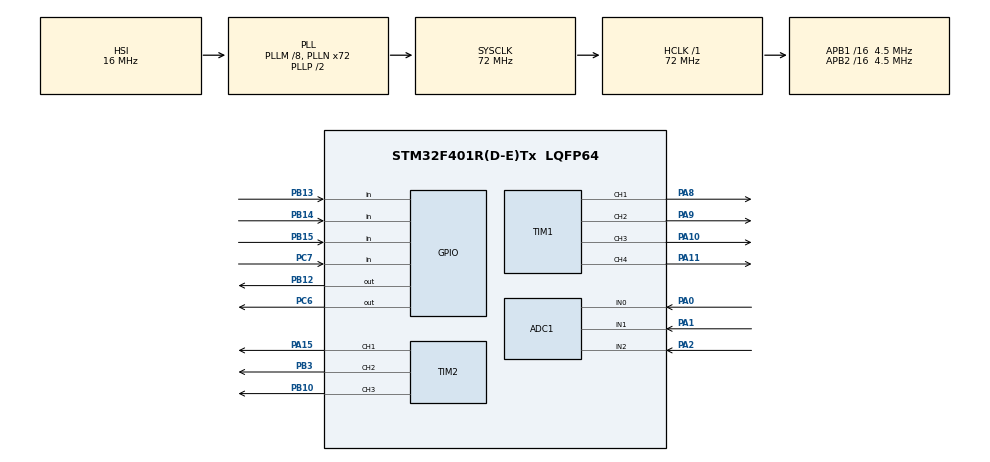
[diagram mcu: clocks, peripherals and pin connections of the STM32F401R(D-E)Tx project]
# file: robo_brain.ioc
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ADC1.Channel-0\#ChannelRegularConversion=ADC_CHANNEL_0
ADC1.NbrOfConversionFlag=1
ADC1.Rank-0\#ChannelRegularConversion=1
ADC1.SamplingTime-0\#ChannelRegularConversion=ADC_SAMPLETIME_3CYCLES
ADC1.master=1
Mcu.Family=STM32F4
Mcu.Name=STM32F401R(D-E)Tx
Mcu.Package=LQFP64
NVIC.PriorityGroup=NVIC_PRIORITYGROUP_4
PA0-WKUP.Signal=ADCx_IN0
PA1.Signal=ADCx_IN1
PA10.Signal=S_TIM1_CH3
PA11.Signal=S_TIM1_CH4
PA15.Signal=S_TIM2_CH1_ETR
PA2.Signal=ADCx_IN2
PA8.Signal=S_TIM1_CH1
PA9.Signal=S_TIM1_CH2
PB10.Signal=S_TIM2_CH3
PB12.Signal=GPIO_Output
PB13.Signal=GPIO_Input
PB14.Signal=GPIO_Input
PB15.Signal=GPIO_Input
PB3.Signal=S_TIM2_CH2
PC6.Signal=GPIO_Output
PC7.Signal=GPIO_Input
ProjectManager.HeapSize=0x200
ProjectManager.StackSize=0x400
ProjectManager.TargetToolchain=Makefile
RCC.48MHZClocksFreq_Value=36000000
RCC.AHBFreq_Value=72000000
RCC.APB1CLKDivider=RCC_HCLK_DIV16
RCC.APB1Freq_Value=4500000
RCC.APB1TimFreq_Value=9000000
RCC.APB2CLKDivider=RCC_HCLK_DIV16
RCC.APB2Freq_Value=4500000
RCC.APB2TimFreq_Value=9000000
RCC.CortexFreq_Value=72000000
RCC.HCLKFreq_Value=72000000
RCC.HSE_VALUE=25000000
RCC.HSI_VALUE=16000000
RCC.LSE_VALUE=32768
RCC.PLLM=8
RCC.PLLN=72
RCC.SYSCLKFreq_VALUE=72000000
RCC.SYSCLKSource=RCC_SYSCLKSOURCE_PLLCLK
RCC.VCOOutputFreq_Value=144000000
SH.ADCx_IN0.0=ADC1_IN0,IN0
SH.ADCx_IN1.0=ADC1_IN1,IN1
SH.ADCx_IN2.0=ADC1_IN2,IN2
SH.S_TIM1_CH1.0=TIM1_CH1,PWM Generation1 CH1
SH.S_TIM1_CH2.0=TIM1_CH2,PWM Generation2 CH2
SH.S_TIM1_CH3.0=TIM1_CH3,PWM Generation3 CH3
SH.S_TIM1_CH4.0=TIM1_CH4,PWM Generation4 CH4
SH.S_TIM2_CH1_ETR.0=TIM2_CH1,PWM Generation1 CH1
SH.S_TIM2_CH2.0=TIM2_CH2,PWM Generation2 CH2
SH.S_TIM2_CH3.0=TIM2_CH3,PWM Generation3 CH3
TIM1.Channel-PWM\ Generation1\ CH1=TIM_CHANNEL_1
TIM1.Channel-PWM\ Generation2\ CH2=TIM_CHANNEL_2
TIM1.Channel-PWM\ Generation3\ CH3=TIM_CHANNEL_3
TIM1.Channel-PWM\ Generation4\ CH4=TIM_CHANNEL_4
TIM2.Channel-PWM\ Generation1\ CH1=TIM_CHANNEL_1
TIM2.Channel-PWM\ Generation2\ CH2=TIM_CHANNEL_2
TIM2.Channel-PWM\ Generation3\ CH3=TIM_CHANNEL_3
VP_TIM1_VS_ClockSourceINT.Mode=Internal
VP_TIM2_VS_ClockSourceINT.Mode=Internal
board=custom

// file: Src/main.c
/**
 ******************************************************************************
 * @file           : main.c
 * @brief          : Main program body
 ******************************************************************************
 ** This notice applies to any and all portions of this file
 * that are not between comment pairs USER CODE BEGIN and
 * USER CODE END. Other portions of this file, whether
 * inserted by the user or by software development tools
 * are owned by their respective copyright owners.
 *
 * COPYRIGHT(c) 2018 STMicroelectronics
 *
 * Redistribution and use in source and binary forms, with or without modification,
 * are permitted provided that the following conditions are met:
 *   1. Redistributions of source code must retain the above copyright notice,
 *      this list of conditions and the following disclaimer.
 *   2. Redistributions in binary form must reproduce the above copyright notice,
 *      this list of conditions and the following disclaimer in the documentation
 *      and/or other materials provided with the distribution.
 *   3. Neither the name of STMicroelectronics nor the names of its contributors
 *      may be used to endorse or promote products derived from this software
 *      without specific prior written permission.
 *
 * THIS SOFTWARE IS PROVIDED BY THE COPYRIGHT HOLDERS AND CONTRIBUTORS "AS IS"
 * AND ANY EXPRESS OR IMPLIED WARRANTIES, INCLUDING, BUT NOT LIMITED TO, THE
 * IMPLIED WARRANTIES OF MERCHANTABILITY AND FITNESS FOR A PARTICULAR PURPOSE ARE
 * DISCLAIMED. IN NO EVENT SHALL THE COPYRIGHT HOLDER OR CONTRIBUTORS BE LIABLE
 * FOR ANY DIRECT, INDIRECT, INCIDENTAL, SPECIAL, EXEMPLARY, OR CONSEQUENTIAL
 * DAMAGES (INCLUDING, BUT NOT LIMITED TO, PROCUREMENT OF SUBSTITUTE GOODS OR
 * SERVICES; LOSS OF USE, DATA, OR PROFITS; OR BUSINESS INTERRUPTION) HOWEVER
 * CAUSED AND ON ANY THEORY OF LIABILITY, WHETHER IN CONTRACT, STRICT LIABILITY,
 * OR TORT (INCLUDING NEGLIGENCE OR OTHERWISE) ARISING IN ANY WAY OUT OF THE USE
 * OF THIS SOFTWARE, EVEN IF ADVISED OF THE POSSIBILITY OF SUCH DAMAGE.
 *
 ******************************************************************************
 */
#include "main.h"
#include "stm32f4xx_hal.h"

/* USER CODE BEGIN Includes */
#include "tm_stm32f4_hcsr04.h"
/* USER CODE END Includes */

ADC_HandleTypeDef hadc1;

TIM_HandleTypeDef htim1;
TIM_HandleTypeDef htim2;

/* USER CODE BEGIN PV */
/* Private variables ---------------------------------------------------------*/

/* USER CODE END PV */

void SystemClock_Config(void);
static void MX_GPIO_Init(void);
static void MX_ADC1_Init(void);
static void MX_TIM1_Init(void);
static void MX_TIM2_Init(void);

void HAL_TIM_MspPostInit(TIM_HandleTypeDef *htim);

/* USER CODE BEGIN PFP */
/* Private function prototypes -----------------------------------------------*/

/* USER CODE END PFP */

int main(void)
{
    /* USER CODE BEGIN 1 */
    TM_HCSR04_t SONAR_LEFT;
    TM_HCSR04_t SONAR_RIGHT;
    /* USER CODE END 1 */

    /* MCU Configuration----------------------------------------------------------*/

    /* Reset of all peripherals, Initializes the Flash interface and the Systick. */
    HAL_Init();

    /* USER CODE BEGIN Init */

    /* Initialize distance sensor1 on pins; ECHO: PC7, TRIGGER: PC6 */
    if (!TM_HCSR04_Init(&SONAR_LEFT, GPIOC, GPIO_PIN_7, GPIOC, GPIO_PIN_6)) {
        /* Sensor is not working */
    }
    /* Initialize distance sensor1 on pins; ECHO: PC12, TRIGGER: PC13 */
    if (!TM_HCSR04_Init(&SONAR_RIGHT, GPIOC, GPIO_PIN_12, GPIOC, GPIO_PIN_13)) {
        /* Sensor is not working */
    }
    /* USER CODE END Init */

    /* Configure the system clock */
    SystemClock_Config();

    /* Initialize all configured peripherals */
    MX_GPIO_Init();
    MX_ADC1_Init();
    MX_TIM1_Init();
    MX_TIM2_Init();

    /* Infinite loop */
    while (1)
    {

    }

}

void SystemClock_Config(void)
{

    RCC_OscInitTypeDef RCC_OscInitStruct;
    RCC_ClkInitTypeDef RCC_ClkInitStruct;

    /**Configure the main internal regulator output voltage
    */
    __HAL_RCC_PWR_CLK_ENABLE();

    __HAL_PWR_VOLTAGESCALING_CONFIG(PWR_REGULATOR_VOLTAGE_SCALE2);

    /**Initializes the CPU, AHB and APB busses clocks
    */
    RCC_OscInitStruct.OscillatorType = RCC_OSCILLATORTYPE_HSI;
    RCC_OscInitStruct.HSIState = RCC_HSI_ON;
    RCC_OscInitStruct.HSICalibrationValue = 16;
    RCC_OscInitStruct.PLL.PLLState = RCC_PLL_ON;
    RCC_OscInitStruct.PLL.PLLSource = RCC_PLLSOURCE_HSI;
    RCC_OscInitStruct.PLL.PLLM = 8;
    RCC_OscInitStruct.PLL.PLLN = 72;
    RCC_OscInitStruct.PLL.PLLP = RCC_PLLP_DIV2;
    RCC_OscInitStruct.PLL.PLLQ = 4;
    if (HAL_RCC_OscConfig(&RCC_OscInitStruct) != HAL_OK)
    {
        _Error_Handler(__FILE__, __LINE__);
    }

    /**Initializes the CPU, AHB and APB busses clocks
    */
    RCC_ClkInitStruct.ClockType = RCC_CLOCKTYPE_HCLK|RCC_CLOCKTYPE_SYSCLK
        |RCC_CLOCKTYPE_PCLK1|RCC_CLOCKTYPE_PCLK2;
    RCC_ClkInitStruct.SYSCLKSource = RCC_SYSCLKSOURCE_PLLCLK;
    RCC_ClkInitStruct.AHBCLKDivider = RCC_SYSCLK_DIV1;
    RCC_ClkInitStruct.APB1CLKDivider = RCC_HCLK_DIV16;
    RCC_ClkInitStruct.APB2CLKDivider = RCC_HCLK_DIV16;

    if (HAL_RCC_ClockConfig(&RCC_ClkInitStruct, FLASH_LATENCY_2) != HAL_OK)
    {
        _Error_Handler(__FILE__, __LINE__);
    }

    /**Configure the Systick interrupt time
    */
    HAL_SYSTICK_Config(HAL_RCC_GetHCLKFreq()/1000);

    /**Configure the Systick
    */
    HAL_SYSTICK_CLKSourceConfig(SYSTICK_CLKSOURCE_HCLK);

    /* SysTick_IRQn interrupt configuration */
    HAL_NVIC_SetPriority(SysTick_IRQn, 0, 0);
}

/* ADC1 init function */
static void MX_ADC1_Init(void)
{

    ADC_ChannelConfTypeDef sConfig;

    /**Configure the global features of the ADC (Clock, Resolution, Data Alignment and number of conversion)
    */
    hadc1.Instance = ADC1;
    hadc1.Init.ClockPrescaler = ADC_CLOCK_SYNC_PCLK_DIV2;
    hadc1.Init.Resolution = ADC_RESOLUTION_12B;
    hadc1.Init.ScanConvMode = DISABLE;
    hadc1.Init.ContinuousConvMode = DISABLE;
    hadc1.Init.DiscontinuousConvMode = DISABLE;
    hadc1.Init.ExternalTrigConvEdge = ADC_EXTERNALTRIGCONVEDGE_NONE;
    hadc1.Init.ExternalTrigConv = ADC_SOFTWARE_START;
    hadc1.Init.DataAlign = ADC_DATAALIGN_RIGHT;
    hadc1.Init.NbrOfConversion = 1;
    hadc1.Init.DMAContinuousRequests = DISABLE;
    hadc1.Init.EOCSelection = ADC_EOC_SINGLE_CONV;
    if (HAL_ADC_Init(&hadc1) != HAL_OK)
    {
        _Error_Handler(__FILE__, __LINE__);
    }

    /**Configure for the selected ADC regular channel its corresponding rank in the sequencer and its sample time.
    */
    sConfig.Channel = ADC_CHANNEL_0;
    sConfig.Rank = 1;
    sConfig.SamplingTime = ADC_SAMPLETIME_3CYCLES;
    if (HAL_ADC_ConfigChannel(&hadc1, &sConfig) != HAL_OK)
    {
        _Error_Handler(__FILE__, __LINE__);
    }

}

/* TIM1 init function */
static void MX_TIM1_Init(void)
{

    TIM_ClockConfigTypeDef sClockSourceConfig;
    TIM_MasterConfigTypeDef sMasterConfig;
    TIM_OC_InitTypeDef sConfigOC;
    TIM_BreakDeadTimeConfigTypeDef sBreakDeadTimeConfig;

    htim1.Instance = TIM1;
    htim1.Init.Prescaler = 0;
    htim1.Init.CounterMode = TIM_COUNTERMODE_UP;
    htim1.Init.Period = 0;
    htim1.Init.ClockDivision = TIM_CLOCKDIVISION_DIV1;
    htim1.Init.RepetitionCounter = 0;
    if (HAL_TIM_Base_Init(&htim1) != HAL_OK)
    {
        _Error_Handler(__FILE__, __LINE__);
    }

    sClockSourceConfig.ClockSource = TIM_CLOCKSOURCE_INTERNAL;
    if (HAL_TIM_ConfigClockSource(&htim1, &sClockSourceConfig) != HAL_OK)
    {
        _Error_Handler(__FILE__, __LINE__);
    }

    if (HAL_TIM_PWM_Init(&htim1) != HAL_OK)
    {
        _Error_Handler(__FILE__, __LINE__);
    }

    sMasterConfig.MasterOutputTrigger = TIM_TRGO_RESET;
    sMasterConfig.MasterSlaveMode = TIM_MASTERSLAVEMODE_DISABLE;
    if (HAL_TIMEx_MasterConfigSynchronization(&htim1, &sMasterConfig) != HAL_OK)
    {
        _Error_Handler(__FILE__, __LINE__);
    }

    sConfigOC.OCMode = TIM_OCMODE_PWM1;
    sConfigOC.Pulse = 0;
    sConfigOC.OCPolarity = TIM_OCPOLARITY_HIGH;
    sConfigOC.OCNPolarity = TIM_OCNPOLARITY_HIGH;
    sConfigOC.OCFastMode = TIM_OCFAST_DISABLE;
    sConfigOC.OCIdleState = TIM_OCIDLESTATE_RESET;
    sConfigOC.OCNIdleState = TIM_OCNIDLESTATE_RESET;
    if (HAL_TIM_PWM_ConfigChannel(&htim1, &sConfigOC, TIM_CHANNEL_1) != HAL_OK)
    {
        _Error_Handler(__FILE__, __LINE__);
    }

    if (HAL_TIM_PWM_ConfigChannel(&htim1, &sConfigOC, TIM_CHANNEL_2) != HAL_OK)
    {
        _Error_Handler(__FILE__, __LINE__);
    }

    if (HAL_TIM_PWM_ConfigChannel(&htim1, &sConfigOC, TIM_CHANNEL_3) != HAL_OK)
    {
        _Error_Handler(__FILE__, __LINE__);
    }

    if (HAL_TIM_PWM_ConfigChannel(&htim1, &sConfigOC, TIM_CHANNEL_4) != HAL_OK)
    {
        _Error_Handler(__FILE__, __LINE__);
    }

    sBreakDeadTimeConfig.OffStateRunMode = TIM_OSSR_DISABLE;
    sBreakDeadTimeConfig.OffStateIDLEMode = TIM_OSSI_DISABLE;
    sBreakDeadTimeConfig.LockLevel = TIM_LOCKLEVEL_OFF;
    sBreakDeadTimeConfig.DeadTime = 0;
    sBreakDeadTimeConfig.BreakState = TIM_BREAK_DISABLE;
    sBreakDeadTimeConfig.BreakPolarity = TIM_BREAKPOLARITY_HIGH;
    sBreakDeadTimeConfig.AutomaticOutput = TIM_AUTOMATICOUTPUT_DISABLE;
    if (HAL_TIMEx_ConfigBreakDeadTime(&htim1, &sBreakDeadTimeConfig) != HAL_OK)
    {
        _Error_Handler(__FILE__, __LINE__);
    }

    HAL_TIM_MspPostInit(&htim1);

}

/* TIM2 init function */
static void MX_TIM2_Init(void)
{

    TIM_ClockConfigTypeDef sClockSourceConfig;
    TIM_MasterConfigTypeDef sMasterConfig;
    TIM_OC_InitTypeDef sConfigOC;

    htim2.Instance = TIM2;
    htim2.Init.Prescaler = 0;
    htim2.Init.CounterMode = TIM_COUNTERMODE_UP;
    htim2.Init.Period = 0;
    htim2.Init.ClockDivision = TIM_CLOCKDIVISION_DIV1;
    if (HAL_TIM_Base_Init(&htim2) != HAL_OK)
    {
        _Error_Handler(__FILE__, __LINE__);
    }

    sClockSourceConfig.ClockSource = TIM_CLOCKSOURCE_INTERNAL;
    if (HAL_TIM_ConfigClockSource(&htim2, &sClockSourceConfig) != HAL_OK)
    {
        _Error_Handler(__FILE__, __LINE__);
    }

    if (HAL_TIM_PWM_Init(&htim2) != HAL_OK)
    {
        _Error_Handler(__FILE__, __LINE__);
    }

    sMasterConfig.MasterOutputTrigger = TIM_TRGO_RESET;
    sMasterConfig.MasterSlaveMode = TIM_MASTERSLAVEMODE_DISABLE;
    if (HAL_TIMEx_MasterConfigSynchronization(&htim2, &sMasterConfig) != HAL_OK)
    {
        _Error_Handler(__FILE__, __LINE__);
    }

    sConfigOC.OCMode = TIM_OCMODE_PWM1;
    sConfigOC.Pulse = 0;
    sConfigOC.OCPolarity = TIM_OCPOLARITY_HIGH;
    sConfigOC.OCFastMode = TIM_OCFAST_DISABLE;
    if (HAL_TIM_PWM_ConfigChannel(&htim2, &sConfigOC, TIM_CHANNEL_1) != HAL_OK)
    {
        _Error_Handler(__FILE__, __LINE__);
    }

    if (HAL_TIM_PWM_ConfigChannel(&htim2, &sConfigOC, TIM_CHANNEL_2) != HAL_OK)
    {
        _Error_Handler(__FILE__, __LINE__);
    }

    if (HAL_TIM_PWM_ConfigChannel(&htim2, &sConfigOC, TIM_CHANNEL_3) != HAL_OK)
    {
        _Error_Handler(__FILE__, __LINE__);
    }

    HAL_TIM_MspPostInit(&htim2);

}

/** Configure pins as
 * Analog
 * Input
 * Output
 * EVENT_OUT
 * EXTI
 */
static void MX_GPIO_Init(void)
{

    GPIO_InitTypeDef GPIO_InitStruct;

    /* GPIO Ports Clock Enable */
    __HAL_RCC_GPIOA_CLK_ENABLE();
    __HAL_RCC_GPIOB_CLK_ENABLE();
    __HAL_RCC_GPIOC_CLK_ENABLE();

    /*Configure GPIO pin Output Level */
    HAL_GPIO_WritePin(GPIOB, GPIO_PIN_12, GPIO_PIN_RESET);

    /*Configure GPIO pin Output Level */
    HAL_GPIO_WritePin(GPIOC, GPIO_PIN_6, GPIO_PIN_RESET);

    /*Configure GPIO pin : PB12 */
    GPIO_InitStruct.Pin = GPIO_PIN_12;
    GPIO_InitStruct.Mode = GPIO_MODE_OUTPUT_PP;
    GPIO_InitStruct.Pull = GPIO_NOPULL;
    GPIO_InitStruct.Speed = GPIO_SPEED_FREQ_LOW;
    HAL_GPIO_Init(GPIOB, &GPIO_InitStruct);

    /*Configure GPIO pins : PB13 PB14 PB15 */
    GPIO_InitStruct.Pin = GPIO_PIN_13|GPIO_PIN_14|GPIO_PIN_15;
    GPIO_InitStruct.Mode = GPIO_MODE_INPUT;
    GPIO_InitStruct.Pull = GPIO_NOPULL;
    HAL_GPIO_Init(GPIOB, &GPIO_InitStruct);

    /*Configure GPIO pin : PC6 */
    GPIO_InitStruct.Pin = GPIO_PIN_6;
    GPIO_InitStruct.Mode = GPIO_MODE_OUTPUT_PP;
    GPIO_InitStruct.Pull = GPIO_NOPULL;
    GPIO_InitStruct.Speed = GPIO_SPEED_FREQ_LOW;
    HAL_GPIO_Init(GPIOC, &GPIO_InitStruct);

    /*Configure GPIO pin : PC7 */
    GPIO_InitStruct.Pin = GPIO_PIN_7;
    GPIO_InitStruct.Mode = GPIO_MODE_INPUT;
    GPIO_InitStruct.Pull = GPIO_NOPULL;
    HAL_GPIO_Init(GPIOC, &GPIO_InitStruct);

}

void _Error_Handler(char *file, int line)
{
    while(1)
    {
    }
}

/************************ (C) COPYRIGHT STMicroelectronics *****END OF FILE****/
